# ESP32-C3 register map
Vendor: ESPRESSIF SYSTEMS (SHANGHAI) CO., LTD.; Series: ESP32 C-Series; File version: 19
CPU: RV32IMC r0p0, little endian, no MPU, no FPU, 0 interrupt priority bits
Address unit: 32 bits
Registers are 32-bit, read-write, reset 0x0 unless marked. A register's access mark holds for its fields unless they carry their own. Offsets are from the block's base; [hi:lo] are bit positions; {n}, {i} and the like mark numbered series.

## DMA — DMA (Direct Memory Access) Controller
Base 0x6003F000
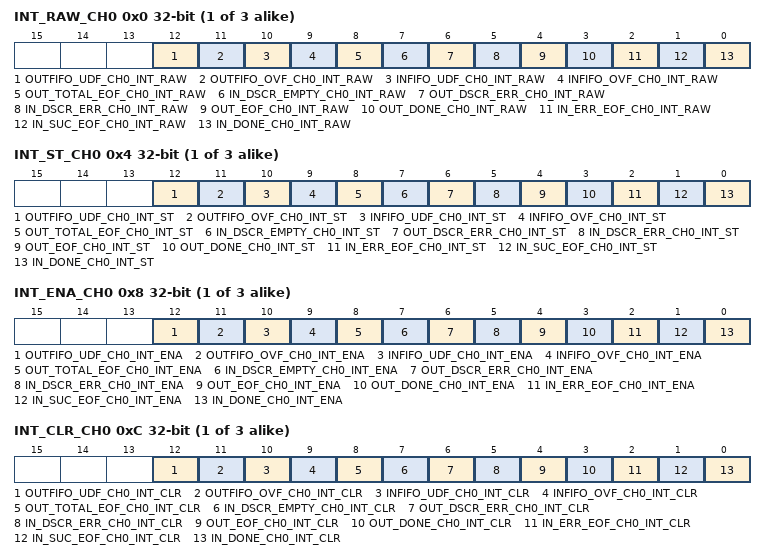
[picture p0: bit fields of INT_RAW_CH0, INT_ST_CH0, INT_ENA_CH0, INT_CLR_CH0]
{0x0+0x10*i} INT_RAW_CH{i} (i=0..2) — DMA_INT_RAW_CH{i}_REG.
  [12] OUTFIFO_UDF_CH{i}_INT_RAW — This raw interrupt bit turns to high level when level 1 fifo of Tx channel {i} is underflow.
  [11] OUTFIFO_OVF_CH{i}_INT_RAW — This raw interrupt bit turns to high level when level 1 fifo of Tx channel {i} is overflow.
  [10] INFIFO_UDF_CH{i}_INT_RAW — This raw interrupt bit turns to high level when level 1 fifo of Rx channel {i} is underflow.
  [9] INFIFO_OVF_CH{i}_INT_RAW — This raw interrupt bit turns to high level when level 1 fifo of Rx channel {i} is overflow.
  [8] OUT_TOTAL_EOF_CH{i}_INT_RAW — The raw interrupt bit turns to high level when data corresponding a outlink (includes one link descriptor or few link descriptors) is transmitted out for Tx channel {i}.
  [7] IN_DSCR_EMPTY_CH{i}_INT_RAW — The raw interrupt bit turns to high level when Rx buffer pointed by inlink is full and receiving data is not completed, but there is no more inlink for Rx channel {i}.
  [6] OUT_DSCR_ERR_CH{i}_INT_RAW — The raw interrupt bit turns to high level when detecting outlink descriptor error, including owner error, the second and third word error of outlink descriptor for Tx channel {i}.
  [5] IN_DSCR_ERR_CH{i}_INT_RAW — The raw interrupt bit turns to high level when detecting inlink descriptor error, including owner error, the second and third word error of inlink descriptor for Rx channel {i}.
  [4] OUT_EOF_CH{i}_INT_RAW — The raw interrupt bit turns to high level when the last data pointed by one outlink descriptor has been read from memory for Tx channel {i}.
  [3] OUT_DONE_CH{i}_INT_RAW — The raw interrupt bit turns to high level when the last data pointed by one outlink descriptor has been transmitted to peripherals for Tx channel {i}.
  [2] IN_ERR_EOF_CH{i}_INT_RAW — The raw interrupt bit turns to high level when data error is detected only in the case that the peripheral is UHCI0 for Rx channel {i}. For other peripherals, this raw interrupt is reserved.
  [1] IN_SUC_EOF_CH{i}_INT_RAW — The raw interrupt bit turns to high level when the last data pointed by one inlink descriptor has been received for Rx channel {i}. For UHCI0, the raw interrupt bit turns to high level when the last data pointed by one inlink descriptor has been received and no data error is detected for Rx channel {i}.
  [0] IN_DONE_CH{i}_INT_RAW — The raw interrupt bit turns to high level when the last data pointed by one inlink descriptor has been received for Rx channel {i}.
{0x4+0x10*i} INT_ST_CH{i} ro (i=0..2) — DMA_INT_ST_CH{i}_REG.
  [12] OUTFIFO_UDF_CH{i}_INT_ST — The raw interrupt status bit for the OUTFIFO_UDF_L1_CH_INT interrupt.
  [11] OUTFIFO_OVF_CH{i}_INT_ST — The raw interrupt status bit for the OUTFIFO_OVF_L1_CH_INT interrupt.
  [10] INFIFO_UDF_CH{i}_INT_ST — The raw interrupt status bit for the INFIFO_UDF_L1_CH_INT interrupt.
  [9] INFIFO_OVF_CH{i}_INT_ST — The raw interrupt status bit for the INFIFO_OVF_L1_CH_INT interrupt.
  [8] OUT_TOTAL_EOF_CH{i}_INT_ST — The raw interrupt status bit for the OUT_TOTAL_EOF_CH_INT interrupt.
  [7] IN_DSCR_EMPTY_CH{i}_INT_ST — The raw interrupt status bit for the IN_DSCR_EMPTY_CH_INT interrupt.
  [6] OUT_DSCR_ERR_CH{i}_INT_ST — The raw interrupt status bit for the OUT_DSCR_ERR_CH_INT interrupt.
  [5] IN_DSCR_ERR_CH{i}_INT_ST — The raw interrupt status bit for the IN_DSCR_ERR_CH_INT interrupt.
  [4] OUT_EOF_CH{i}_INT_ST — The raw interrupt status bit for the OUT_EOF_CH_INT interrupt.
  [3] OUT_DONE_CH{i}_INT_ST — The raw interrupt status bit for the OUT_DONE_CH_INT interrupt.
  [2] IN_ERR_EOF_CH{i}_INT_ST — The raw interrupt status bit for the IN_ERR_EOF_CH_INT interrupt.
  [1] IN_SUC_EOF_CH{i}_INT_ST — The raw interrupt status bit for the IN_SUC_EOF_CH_INT interrupt.
  [0] IN_DONE_CH{i}_INT_ST — The raw interrupt status bit for the IN_DONE_CH_INT interrupt.
{0x8+0x10*i} INT_ENA_CH{i} (i=0..2) — DMA_INT_ENA_CH{i}_REG.
  [12] OUTFIFO_UDF_CH{i}_INT_ENA — The interrupt enable bit for the OUTFIFO_UDF_L1_CH_INT interrupt.
  [11] OUTFIFO_OVF_CH{i}_INT_ENA — The interrupt enable bit for the OUTFIFO_OVF_L1_CH_INT interrupt.
  [10] INFIFO_UDF_CH{i}_INT_ENA — The interrupt enable bit for the INFIFO_UDF_L1_CH_INT interrupt.
  [9] INFIFO_OVF_CH{i}_INT_ENA — The interrupt enable bit for the INFIFO_OVF_L1_CH_INT interrupt.
  [8] OUT_TOTAL_EOF_CH{i}_INT_ENA — The interrupt enable bit for the OUT_TOTAL_EOF_CH_INT interrupt.
  [7] IN_DSCR_EMPTY_CH{i}_INT_ENA — The interrupt enable bit for the IN_DSCR_EMPTY_CH_INT interrupt.
  [6] OUT_DSCR_ERR_CH{i}_INT_ENA — The interrupt enable bit for the OUT_DSCR_ERR_CH_INT interrupt.
  [5] IN_DSCR_ERR_CH{i}_INT_ENA — The interrupt enable bit for the IN_DSCR_ERR_CH_INT interrupt.
  [4] OUT_EOF_CH{i}_INT_ENA — The interrupt enable bit for the OUT_EOF_CH_INT interrupt.
  [3] OUT_DONE_CH{i}_INT_ENA — The interrupt enable bit for the OUT_DONE_CH_INT interrupt.
  [2] IN_ERR_EOF_CH{i}_INT_ENA — The interrupt enable bit for the IN_ERR_EOF_CH_INT interrupt.
  [1] IN_SUC_EOF_CH{i}_INT_ENA — The interrupt enable bit for the IN_SUC_EOF_CH_INT interrupt.
  [0] IN_DONE_CH{i}_INT_ENA — The interrupt enable bit for the IN_DONE_CH_INT interrupt.
{0xC+0x10*i} INT_CLR_CH{i} wo (i=0..2) — DMA_INT_CLR_CH{i}_REG.
  [12] OUTFIFO_UDF_CH{i}_INT_CLR — Set this bit to clear the OUTFIFO_UDF_L1_CH_INT interrupt.
  [11] OUTFIFO_OVF_CH{i}_INT_CLR — Set this bit to clear the OUTFIFO_OVF_L1_CH_INT interrupt.
  [10] INFIFO_UDF_CH{i}_INT_CLR — Set this bit to clear the INFIFO_UDF_L1_CH_INT interrupt.
  [9] INFIFO_OVF_CH{i}_INT_CLR — Set this bit to clear the INFIFO_OVF_L1_CH_INT interrupt.
  [8] OUT_TOTAL_EOF_CH{i}_INT_CLR — Set this bit to clear the OUT_TOTAL_EOF_CH_INT interrupt.
  [7] IN_DSCR_EMPTY_CH{i}_INT_CLR — Set this bit to clear the IN_DSCR_EMPTY_CH_INT interrupt.
  [6] OUT_DSCR_ERR_CH{i}_INT_CLR — Set this bit to clear the OUT_DSCR_ERR_CH_INT interrupt.
  [5] IN_DSCR_ERR_CH{i}_INT_CLR — Set this bit to clear the IN_DSCR_ERR_CH_INT interrupt.
  [4] OUT_EOF_CH{i}_INT_CLR — Set this bit to clear the OUT_EOF_CH_INT interrupt.
  [3] OUT_DONE_CH{i}_INT_CLR — Set this bit to clear the OUT_DONE_CH_INT interrupt.
  [2] IN_ERR_EOF_CH{i}_INT_CLR — Set this bit to clear the IN_ERR_EOF_CH_INT interrupt.
  [1] IN_SUC_EOF_CH{i}_INT_CLR — Set this bit to clear the IN_SUC_EOF_CH_INT interrupt.
  [0] IN_DONE_CH{i}_INT_CLR — Set this bit to clear the IN_DONE_CH_INT interrupt.
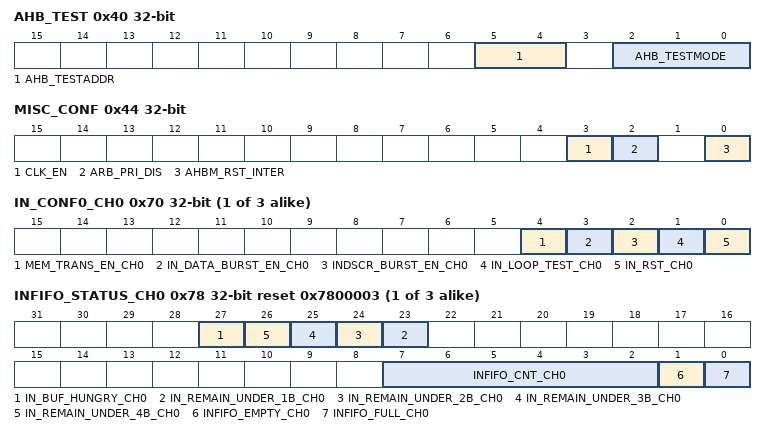
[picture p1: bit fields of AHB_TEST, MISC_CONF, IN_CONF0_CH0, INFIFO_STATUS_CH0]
0x40 AHB_TEST — DMA_AHB_TEST_REG.
  [5:4] AHB_TESTADDR — reserved
  [2:0] AHB_TESTMODE — reserved
0x44 MISC_CONF — DMA_MISC_CONF_REG.
  [3] CLK_EN — reg_clk_en
  [2] ARB_PRI_DIS — Set this bit to disable priority arbitration function.
  [0] AHBM_RST_INTER — Set this bit, then clear this bit to reset the internal ahb FSM.
0x48 DATE reset 0x2008250 — DMA_DATE_REG.
  [31:0] DATE — register version.
{0x70+0xC0*i} IN_CONF0_CH{i} (i=0..2) — DMA_IN_CONF0_CH{i}_REG.
  [4] MEM_TRANS_EN_CH{i} — Set this bit 1 to enable automatic transmitting data from memory to memory via DMA.
  [3] IN_DATA_BURST_EN_CH{i} — Set this bit to 1 to enable INCR burst transfer for Rx channel {i} receiving data when accessing internal SRAM.
  [2] INDSCR_BURST_EN_CH{i} — Set this bit to 1 to enable INCR burst transfer for Rx channel {i} reading link descriptor when accessing internal SRAM.
  [1] IN_LOOP_TEST_CH{i} — reserved
  [0] IN_RST_CH{i} — This bit is used to reset DMA channel {i} Rx FSM and Rx FIFO pointer.
{0x74+0xC0*i} IN_CONF1_CH{i} (i=0..2) — DMA_IN_CONF1_CH{i}_REG.
  [12] IN_CHECK_OWNER_CH{i} — Set this bit to enable checking the owner attribute of the link descriptor.
{0x78+0xC0*i} INFIFO_STATUS_CH{i} ro reset 0x7800003 (i=0..2) — DMA_INFIFO_STATUS_CH{i}_REG.
  [27] IN_BUF_HUNGRY_CH{i} — reserved
  [n+22] IN_REMAIN_UNDER_{n}B_CH{i} (n=1..4) — reserved
  [7:2] INFIFO_CNT_CH{i} — The register stores the byte number of the data in L1 Rx FIFO for Rx channel {i}.
  [1] INFIFO_EMPTY_CH{i} — L1 Rx FIFO empty signal for Rx channel {i}.
  [0] INFIFO_FULL_CH{i} — L1 Rx FIFO full signal for Rx channel {i}.
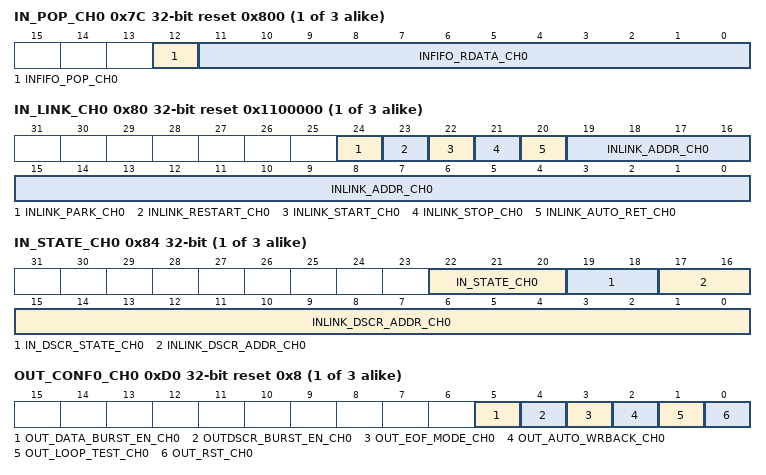
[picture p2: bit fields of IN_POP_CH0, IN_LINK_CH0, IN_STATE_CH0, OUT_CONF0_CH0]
{0x7C+0xC0*i} IN_POP_CH{i} access per field reset 0x800 (i=0..2) — DMA_IN_POP_CH{i}_REG.
  [12] INFIFO_POP_CH{i} rw — Set this bit to pop data from DMA FIFO.
  [11:0] INFIFO_RDATA_CH{i} ro — This register stores the data popping from DMA FIFO.
{0x80+0xC0*i} IN_LINK_CH{i} access per field reset 0x1100000 (i=0..2) — DMA_IN_LINK_CH{i}_REG.
  [24] INLINK_PARK_CH{i} ro — 1: the inlink descriptor's FSM is in idle state. 0: the inlink descriptor's FSM is working.
  [23] INLINK_RESTART_CH{i} rw — Set this bit to mount a new inlink descriptor.
  [22] INLINK_START_CH{i} rw — Set this bit to start dealing with the inlink descriptors.
  [21] INLINK_STOP_CH{i} rw — Set this bit to stop dealing with the inlink descriptors.
  [20] INLINK_AUTO_RET_CH{i} rw — Set this bit to return to current inlink descriptor's address, when there are some errors in current receiving data.
  [19:0] INLINK_ADDR_CH{i} rw — This register stores the 20 least significant bits of the first inlink descriptor's address.
{0x84+0xC0*i} IN_STATE_CH{i} ro (i=0..2) — DMA_IN_STATE_CH{i}_REG.
  [22:20] IN_STATE_CH{i} — reserved
  [19:18] IN_DSCR_STATE_CH{i} — reserved
  [17:0] INLINK_DSCR_ADDR_CH{i} — This register stores the current inlink descriptor's address.
{0x88+0xC0*i} IN_SUC_EOF_DES_ADDR_CH{i} ro (i=0..2) — DMA_IN_SUC_EOF_DES_ADDR_CH{i}_REG.
  [31:0] IN_SUC_EOF_DES_ADDR_CH{i} — This register stores the address of the inlink descriptor when the EOF bit in this descriptor is 1.
{0x8C+0xC0*i} IN_ERR_EOF_DES_ADDR_CH{i} ro (i=0..2) — DMA_IN_ERR_EOF_DES_ADDR_CH{i}_REG.
  [31:0] IN_ERR_EOF_DES_ADDR_CH{i} — This register stores the address of the inlink descriptor when there are some errors in current receiving data. Only used when peripheral is UHCI0.
{0x90+0xC0*i} IN_DSCR_CH{i} ro (i=0..2) — DMA_IN_DSCR_CH{i}_REG.
  [31:0] INLINK_DSCR_CH{i} — The address of the current inlink descriptor x.
{0x94+0xC0*i} IN_DSCR_BF0_CH{i} ro (i=0..2) — DMA_IN_DSCR_BF0_CH{i}_REG.
  [31:0] INLINK_DSCR_BF0_CH{i} — The address of the last inlink descriptor x-1.
{0x98+0xC0*i} IN_DSCR_BF1_CH{i} ro (i=0..2) — DMA_IN_DSCR_BF1_CH{i}_REG.
  [31:0] INLINK_DSCR_BF1_CH{i} — The address of the second-to-last inlink descriptor x-2.
{0x9C+0xC0*i} IN_PRI_CH{i} (i=0..2) — DMA_IN_PRI_CH{i}_REG.
  [3:0] RX_PRI_CH{i} — The priority of Rx channel {i}. The larger of the value, the higher of the priority.
{0xA0+0xC0*i} IN_PERI_SEL_CH{i} reset 0x3F (i=0..2) — DMA_IN_PERI_SEL_CH{i}_REG.
  [5:0] PERI_IN_SEL_CH{i} — This register is used to select peripheral for Rx channel {i}. 0:SPI2. 1: reserved. 2: UHCI0. 3: I2S0. 4: reserved. 5: reserved. 6: AES. 7: SHA. 8: ADC_DAC.
{0xD0+0xC0*i} OUT_CONF0_CH{i} reset 0x8 (i=0..2) — DMA_OUT_CONF0_CH{i}_REG.
  [5] OUT_DATA_BURST_EN_CH{i} — Set this bit to 1 to enable INCR burst transfer for Tx channel {i} transmitting data when accessing internal SRAM.
  [4] OUTDSCR_BURST_EN_CH{i} — Set this bit to 1 to enable INCR burst transfer for Tx channel {i} reading link descriptor when accessing internal SRAM.
  [3] OUT_EOF_MODE_CH{i} — EOF flag generation mode when transmitting data. 1: EOF flag for Tx channel {i} is generated when data need to transmit has been popped from FIFO in DMA
  [2] OUT_AUTO_WRBACK_CH{i} — Set this bit to enable automatic outlink-writeback when all the data in tx buffer has been transmitted.
  [1] OUT_LOOP_TEST_CH{i} — reserved
  [0] OUT_RST_CH{i} — This bit is used to reset DMA channel {i} Tx FSM and Tx FIFO pointer.
{0xD4+0xC0*i} OUT_CONF1_CH{i} (i=0..2) — DMA_OUT_CONF1_CH{i}_REG.
  [12] OUT_CHECK_OWNER_CH{i} — Set this bit to enable checking the owner attribute of the link descriptor.
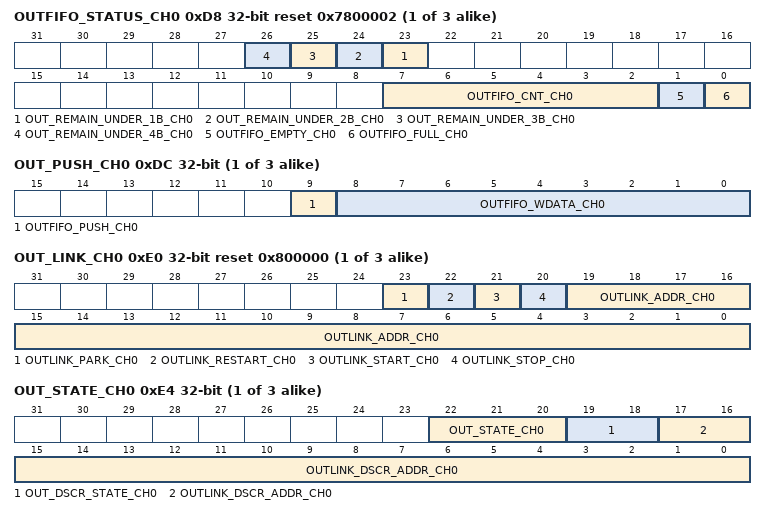
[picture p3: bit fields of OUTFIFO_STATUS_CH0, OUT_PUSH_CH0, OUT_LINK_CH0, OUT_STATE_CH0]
{0xD8+0xC0*i} OUTFIFO_STATUS_CH{i} ro reset 0x7800002 (i=0..2) — DMA_OUTFIFO_STATUS_CH{i}_REG.
  [n+22] OUT_REMAIN_UNDER_{n}B_CH{i} (n=1..4) — reserved
  [7:2] OUTFIFO_CNT_CH{i} — The register stores the byte number of the data in L1 Tx FIFO for Tx channel {i}.
  [1] OUTFIFO_EMPTY_CH{i} — L1 Tx FIFO empty signal for Tx channel {i}.
  [0] OUTFIFO_FULL_CH{i} — L1 Tx FIFO full signal for Tx channel {i}.
{0xDC+0xC0*i} OUT_PUSH_CH{i} (i=0..2) — DMA_OUT_PUSH_CH{i}_REG.
  [9] OUTFIFO_PUSH_CH{i} — Set this bit to push data into DMA FIFO.
  [8:0] OUTFIFO_WDATA_CH{i} — This register stores the data that need to be pushed into DMA FIFO.
{0xE0+0xC0*i} OUT_LINK_CH{i} access per field reset 0x800000 (i=0..2) — DMA_OUT_LINK_CH{i}_REG.
  [23] OUTLINK_PARK_CH{i} ro — 1: the outlink descriptor's FSM is in idle state. 0: the outlink descriptor's FSM is working.
  [22] OUTLINK_RESTART_CH{i} rw — Set this bit to restart a new outlink from the last address.
  [21] OUTLINK_START_CH{i} rw — Set this bit to start dealing with the outlink descriptors.
  [20] OUTLINK_STOP_CH{i} rw — Set this bit to stop dealing with the outlink descriptors.
  [19:0] OUTLINK_ADDR_CH{i} rw — This register stores the 20 least significant bits of the first outlink descriptor's address.
{0xE4+0xC0*i} OUT_STATE_CH{i} ro (i=0..2) — DMA_OUT_STATE_CH{i}_REG.
  [22:20] OUT_STATE_CH{i} — reserved
  [19:18] OUT_DSCR_STATE_CH{i} — reserved
  [17:0] OUTLINK_DSCR_ADDR_CH{i} — This register stores the current outlink descriptor's address.
{0xE8+0xC0*i} OUT_EOF_DES_ADDR_CH{i} ro (i=0..2) — DMA_OUT_EOF_DES_ADDR_CH{i}_REG.
  [31:0] OUT_EOF_DES_ADDR_CH{i} — This register stores the address of the outlink descriptor when the EOF bit in this descriptor is 1.
{0xEC+0xC0*i} OUT_EOF_BFR_DES_ADDR_CH{i} ro (i=0..2) — DMA_OUT_EOF_BFR_DES_ADDR_CH{i}_REG.
  [31:0] OUT_EOF_BFR_DES_ADDR_CH{i} — This register stores the address of the outlink descriptor before the last outlink descriptor.
{0xF0+0xC0*i} OUT_DSCR_CH{i} ro (i=0..2) — DMA_OUT_DSCR_CH{i}_REG.
  [31:0] OUTLINK_DSCR_CH{i} — The address of the current outlink descriptor y.
{0xF4+0xC0*i} OUT_DSCR_BF0_CH{i} ro (i=0..2) — DMA_OUT_DSCR_BF0_CH{i}_REG.
  [31:0] OUTLINK_DSCR_BF0_CH{i} — The address of the last outlink descriptor y-1.
{0xF8+0xC0*i} OUT_DSCR_BF1_CH{i} ro (i=0..2) — DMA_OUT_DSCR_BF1_CH{i}_REG.
  [31:0] OUTLINK_DSCR_BF1_CH{i} — The address of the second-to-last inlink descriptor x-2.
{0xFC+0xC0*i} OUT_PRI_CH{i} (i=0..2) — DMA_OUT_PRI_CH{i}_REG.
  [3:0] TX_PRI_CH{i} — The priority of Tx channel {i}. The larger of the value, the higher of the priority.
{0x100+0xC0*i} OUT_PERI_SEL_CH{i} reset 0x3F (i=0..2) — DMA_OUT_PERI_SEL_CH{i}_REG.
  [5:0] PERI_OUT_SEL_CH{i} — This register is used to select peripheral for Tx channel {i}. 0:SPI2. 1: reserved. 2: UHCI0. 3: I2S0. 4: reserved. 5: reserved. 6: AES. 7: SHA. 8: ADC_DAC.
